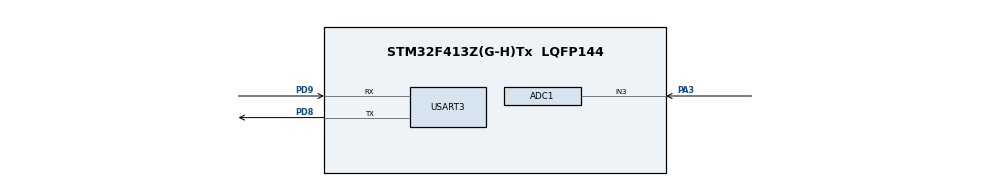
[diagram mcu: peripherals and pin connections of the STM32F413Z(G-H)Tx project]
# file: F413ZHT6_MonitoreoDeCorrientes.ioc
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ADC1.Channel-0\#ChannelRegularConversion=ADC_CHANNEL_3
ADC1.NbrOfConversionFlag=1
ADC1.Rank-0\#ChannelRegularConversion=1
ADC1.SamplingTime-0\#ChannelRegularConversion=ADC_SAMPLETIME_3CYCLES
ADC1.master=1
Mcu.Family=STM32F4
Mcu.Name=STM32F413Z(G-H)Tx
Mcu.Package=LQFP144
NVIC.PriorityGroup=NVIC_PRIORITYGROUP_4
NVIC.TIM1_UP_TIM10_IRQn=true\:15\:0\:false\:false\:true\:false\:true\:true
NVIC.TimeBase=TIM1_UP_TIM10_IRQn
NVIC.TimeBaseIP=TIM1
NVIC.USART3_IRQn=true\:0\:0\:false\:false\:true\:true\:true\:true
PA13.Mode=Serial_Wire
PA13.Signal=SYS_JTMS-SWDIO
PA14.Mode=Serial_Wire
PA14.Signal=SYS_JTCK-SWCLK
PA3.Signal=ADCx_IN3
PD8.Mode=Asynchronous
PD8.Signal=USART3_TX
PD9.Mode=Asynchronous
PD9.Signal=USART3_RX
ProjectManager.HeapSize=0x200
ProjectManager.StackSize=0x400
ProjectManager.TargetToolchain=STM32CubeIDE
RCC.CortexFreq_Value=16000000
RCC.USBFreq_Value=96000000
RCC.VCOOutputFreq_Value=192000000
SH.ADCx_IN3.0=ADC1_IN3,IN3
USART3.VirtualMode=VM_ASYNC
VP_SYS_VS_tim1.Mode=TIM1
board=custom

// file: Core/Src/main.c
/* USER CODE BEGIN Header */
/**
  ******************************************************************************
  * @file           : main.c
  * @brief          : Main program body
  ******************************************************************************
  * @attention
  *
  * Copyright (c) 2022 STMicroelectronics.
  * All rights reserved.
  *
  * This software is licensed under terms that can be found in the LICENSE file
  * in the root directory of this software component.
  * If no LICENSE file comes with this software, it is provided AS-IS.
  *
  ******************************************************************************
  */
/* USER CODE END Header */
#include "main.h"
#include <stdio.h>
#include <string.h>

ADC_HandleTypeDef hadc1;

UART_HandleTypeDef huart3;

void SystemClock_Config(void);
static void MX_GPIO_Init(void);
static void MX_USART3_UART_Init(void);
static void MX_ADC1_Init(void);

/* USER CODE BEGIN 0 */
/*uint8_t buffer[4];*/

/* USER CODE END 0 */

int main(void)
{
  /* USER CODE BEGIN 1 */

	uint16_t raw;
	char msg[10];

  /* USER CODE END 1 */

  /* MCU Configuration--------------------------------------------------------*/

  /* Reset of all peripherals, Initializes the Flash interface and the Systick. */
  HAL_Init();

  /* Configure the system clock */
  SystemClock_Config();

  /* Initialize all configured peripherals */
  MX_GPIO_Init();
  MX_USART3_UART_Init();
  MX_ADC1_Init();
  /* USER CODE BEGIN 2 */
  /*HAL_UART_Receive_IT(&huart3, buffer, sizeof(buffer));*/
  /*uint8_t buffer[] = "Hello from board2\r\n";*/

  /* USER CODE END 2 */

  /* Infinite loop */
  /* USER CODE BEGIN WHILE */
  while (1)
  {
	  // Get ADC value
	  HAL_ADC_Start(&hadc1);
	  HAL_ADC_PollForConversion(&hadc1, HAL_MAX_DELAY);
	  raw = HAL_ADC_GetValue(&hadc1);

    /* USER CODE END WHILE */
	  sprintf(msg, "%hu\r\n", raw);
	  HAL_StatusTypeDef status = HAL_UART_Transmit(&huart3, (uint8_t*)msg, strlen(msg), 100);
	  if(status != HAL_OK);
	  HAL_Delay(1000);
  }
}

void SystemClock_Config(void)
{
  RCC_OscInitTypeDef RCC_OscInitStruct = {0};
  RCC_ClkInitTypeDef RCC_ClkInitStruct = {0};

  /** Configure the main internal regulator output voltage
  */
  __HAL_RCC_PWR_CLK_ENABLE();
  __HAL_PWR_VOLTAGESCALING_CONFIG(PWR_REGULATOR_VOLTAGE_SCALE1);

  /** Initializes the RCC Oscillators according to the specified parameters
  * in the RCC_OscInitTypeDef structure.
  */
  RCC_OscInitStruct.OscillatorType = RCC_OSCILLATORTYPE_HSI;
  RCC_OscInitStruct.HSIState = RCC_HSI_ON;
  RCC_OscInitStruct.HSICalibrationValue = RCC_HSICALIBRATION_DEFAULT;
  RCC_OscInitStruct.PLL.PLLState = RCC_PLL_NONE;
  if (HAL_RCC_OscConfig(&RCC_OscInitStruct) != HAL_OK)
  {
    Error_Handler();
  }

  /** Initializes the CPU, AHB and APB buses clocks
  */
  RCC_ClkInitStruct.ClockType = RCC_CLOCKTYPE_HCLK|RCC_CLOCKTYPE_SYSCLK
                              |RCC_CLOCKTYPE_PCLK1|RCC_CLOCKTYPE_PCLK2;
  RCC_ClkInitStruct.SYSCLKSource = RCC_SYSCLKSOURCE_HSI;
  RCC_ClkInitStruct.AHBCLKDivider = RCC_SYSCLK_DIV1;
  RCC_ClkInitStruct.APB1CLKDivider = RCC_HCLK_DIV1;
  RCC_ClkInitStruct.APB2CLKDivider = RCC_HCLK_DIV1;

  if (HAL_RCC_ClockConfig(&RCC_ClkInitStruct, FLASH_LATENCY_0) != HAL_OK)
  {
    Error_Handler();
  }
}

static void MX_ADC1_Init(void)
{

  ADC_ChannelConfTypeDef sConfig = {0};

  /** Configure the global features of the ADC (Clock, Resolution, Data Alignment and number of conversion)
  */
  hadc1.Instance = ADC1;
  hadc1.Init.ClockPrescaler = ADC_CLOCK_SYNC_PCLK_DIV2;
  hadc1.Init.Resolution = ADC_RESOLUTION_12B;
  hadc1.Init.ScanConvMode = DISABLE;
  hadc1.Init.ContinuousConvMode = DISABLE;
  hadc1.Init.DiscontinuousConvMode = DISABLE;
  hadc1.Init.ExternalTrigConvEdge = ADC_EXTERNALTRIGCONVEDGE_NONE;
  hadc1.Init.ExternalTrigConv = ADC_SOFTWARE_START;
  hadc1.Init.DataAlign = ADC_DATAALIGN_RIGHT;
  hadc1.Init.NbrOfConversion = 1;
  hadc1.Init.DMAContinuousRequests = DISABLE;
  hadc1.Init.EOCSelection = ADC_EOC_SINGLE_CONV;
  if (HAL_ADC_Init(&hadc1) != HAL_OK)
  {
    Error_Handler();
  }

  /** Configure for the selected ADC regular channel its corresponding rank in the sequencer and its sample time.
  */
  sConfig.Channel = ADC_CHANNEL_3;
  sConfig.Rank = 1;
  sConfig.SamplingTime = ADC_SAMPLETIME_3CYCLES;
  if (HAL_ADC_ConfigChannel(&hadc1, &sConfig) != HAL_OK)
  {
    Error_Handler();
  }

}

static void MX_USART3_UART_Init(void)
{

  huart3.Instance = USART3;
  huart3.Init.BaudRate = 115200;
  huart3.Init.WordLength = UART_WORDLENGTH_8B;
  huart3.Init.StopBits = UART_STOPBITS_1;
  huart3.Init.Parity = UART_PARITY_NONE;
  huart3.Init.Mode = UART_MODE_TX_RX;
  huart3.Init.HwFlowCtl = UART_HWCONTROL_NONE;
  huart3.Init.OverSampling = UART_OVERSAMPLING_16;
  if (HAL_UART_Init(&huart3) != HAL_OK)
  {
    Error_Handler();
  }

}

static void MX_GPIO_Init(void)
{

  /* GPIO Ports Clock Enable */
  __HAL_RCC_GPIOA_CLK_ENABLE();
  __HAL_RCC_GPIOD_CLK_ENABLE();

}

/* USER CODE BEGIN 4 */
/*void HAL_UART_RxCpltCallback(UART_HandleTypeDef *huart) {
	HAL_UART_Receive_IT(&huart3, buffer, sizeof(buffer));
	HAL_UART_Transmit_IT(&huart3, buffer, sizeof(buffer));
}*/
/* USER CODE END 4 */

void HAL_TIM_PeriodElapsedCallback(TIM_HandleTypeDef *htim)
{
  if (htim->Instance == TIM1) {
    HAL_IncTick();
  }
}

void Error_Handler(void)
{
  __disable_irq();
  while (1)
  {
  }
}
